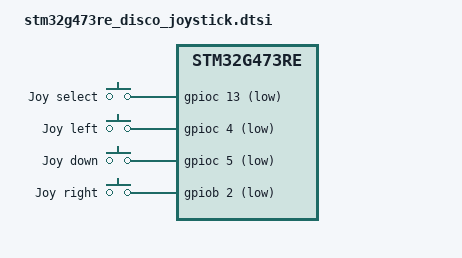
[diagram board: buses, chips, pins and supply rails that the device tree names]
/*
 * Copyright (c) 2020 Rohan Dey
 *
 * SPDX-License-Identifier: Apache-2.0
 */

&c201 {
	joystick_keys {
		compatible = "gpio-keys";
		joysel: joysel {
			gpios = <&gpioc 13 (GPIO_ACTIVE_LOW | GPIO_PULL_UP)>;
			label = "Joy select";
		};
		joyleft: joyleft {
			gpios = <&gpioc 4 (GPIO_ACTIVE_LOW | GPIO_PULL_UP)>;
			label = "Joy left";
		};
		joydown: joydown {
			gpios = <&gpioc 5 (GPIO_ACTIVE_LOW | GPIO_PULL_UP)>;
			label = "Joy down";
		};
		joyright: joyright {
			gpios = <&gpiob 2 (GPIO_ACTIVE_LOW | GPIO_PULL_UP)>;
			label = "Joy right";
		};
		/*joyup: joyup {
			gpios = <&gpiob 10 (GPIO_ACTIVE_LOW | GPIO_PULL_UP)>;
			label = "Joy up";
		};*/
	};
};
